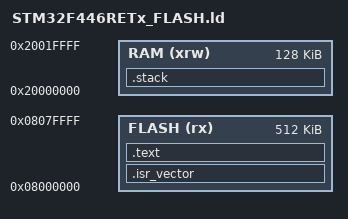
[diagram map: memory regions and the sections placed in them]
MEMORY
{
  RAM    (xrw)    : ORIGIN = 0x20000000,   LENGTH = 128K
  FLASH   (rx)    : ORIGIN = 0x08000000,   LENGTH = 512K
}

_stack_size = 4096;

SECTIONS
{
  .isr_vector :
  {
    . = ALIGN(4);
    KEEP(*(.isr_vector))
    . = ALIGN(4);
  } >FLASH

  .text :
  {
    . = ALIGN(4);
    *(.text)
    *(.text*)
    . = ALIGN(4);
  } >FLASH

  /* Stack section */
  .stack (NOLOAD):
  {
    . = ALIGN(8);
    _sstack = .;
    . = . + _stack_size;
    . = ALIGN(8);
    _estack = .;
  } >RAM
}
